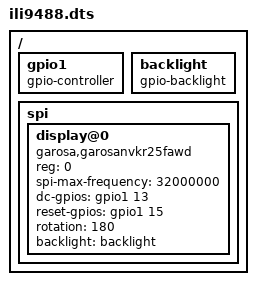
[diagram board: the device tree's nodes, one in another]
// SPDX-License-Identifier: GPL-2.0-only
/dts-v1/;

#include <dt-bindings/gpio/gpio.h>

/{
	gpio1: gpio1 {
		gpio-controller;
		#gpio-cells = <2>; // Specify pin (cell 1) and consumer flags (cell 2)
	};

	backlight: backlight {
		compatible = "gpio-backlight";
//		gpios = <&gpio1 22 GPIO_ACTIVE_HIGH>;
	};

	spi {
		#address-cells = <1>;
		#size-cells = <0>;

		display@0 {
			status = "okay"; // enable node
			compatible = "garosa,garosanvkr25fawd", "ilitek,ili9488";
			reg = <0>;
			spi-max-frequency = <32000000>;
			dc-gpios = <&gpio1 13 GPIO_ACTIVE_HIGH>;
			reset-gpios = <&gpio1 15 GPIO_ACTIVE_HIGH>;
			rotation = <180>;
			backlight = <&backlight>;
		};
	};
};
